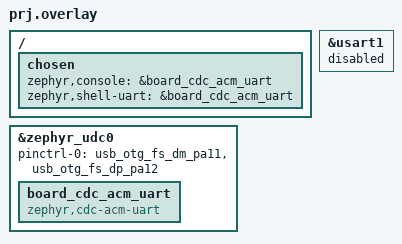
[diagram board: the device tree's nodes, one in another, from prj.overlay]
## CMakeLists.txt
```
cmake_minimum_required(VERSION 3.20.0)

# If a project devicetree overlay exists, pass it to the Zephyr build
# so the overlay is applied during the initial configure step.
if(EXISTS "${CMAKE_CURRENT_SOURCE_DIR}/prj.overlay")
	set(DTC_OVERLAY_FILE "${CMAKE_CURRENT_SOURCE_DIR}/prj.overlay" CACHE STRING "Device tree overlay file for project")
endif()

find_package(Zephyr REQUIRED HINTS $ENV{ZEPHYR_BASE})

project(stm32f411_template)

target_sources(app PRIVATE src/main.c)
```

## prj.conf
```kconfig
# STM32F411 template – Kconfig fragments
# Board: blackpill_f411ce  (WeAct BlackPill STM32F411CEU6)
# Build: cmake -B build -DBOARD=blackpill_f411ce . && cmake --build build -j4

CONFIG_GPIO=y

# Enable USB device stack and CDC-ACM (USB serial)
CONFIG_USB_DEVICE_STACK=y
CONFIG_USB_CDC_ACM=y

# Route console/printk to the console backend (which will be the CDC ACM device)
CONFIG_CONSOLE=y
CONFIG_STDOUT_CONSOLE=y
CONFIG_PRINTK=y
CONFIG_LOG=y
# Lower default log level to reduce driver debug noise on CDC
# 3 = LOG_LEVEL_INF
CONFIG_LOG_DEFAULT_LEVEL=3

# Enable the UART console so the CDC ACM UART driver can be used
CONFIG_UART_CONSOLE=y

# Use the UART log backend (the CDC ACM node exposes a UART device)
CONFIG_LOG_BACKEND_UART=y
CONFIG_LOG_BACKEND_UART_AUTOSTART=y

# USB Device identity - override the Zephyr test defaults
# Replace these with your vendor's assigned IDs for production
CONFIG_USB_DEVICE_VID=0x0483
CONFIG_USB_DEVICE_PID=0x5740
CONFIG_USB_DEVICE_MANUFACTURER="WeAct"
CONFIG_USB_DEVICE_PRODUCT="BlackPill F411 CDC"

# Per-module USB log levels are controlled indirectly; use `CONFIG_LOG_DEFAULT_LEVEL` above.
```

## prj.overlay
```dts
/* Project devicetree overlay: route console to USB CDC ACM */

/ {
    chosen {
        zephyr,console = &board_cdc_acm_uart;
        zephyr,shell-uart = &board_cdc_acm_uart;
    };
};

&zephyr_udc0 {
    /* DP/DM pins for the STM32 USB driver; omit VBUS pin to disable hardware sensing */
    pinctrl-0 = <&usb_otg_fs_dm_pa11 &usb_otg_fs_dp_pa12>;
    pinctrl-names = "default";

    board_cdc_acm_uart: board_cdc_acm_uart {
        compatible = "zephyr,cdc-acm-uart";
        status = "okay";
    };
};

/* Disable onboard USART1 so it doesn't claim PA9 (VBUS) on this board */
&usart1 {
    status = "disabled";
};
```

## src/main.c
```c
/**
 * STM32F411 Template - Zephyr RTOS v4.2.2
 * Board  : blackpill_f411ce (WeAct BlackPill STM32F411CEU6)
 * LED    : PC13 (aliased as led0 in board DTS)
 *
 * Build (container):
 *   cmake -B build -DBOARD=blackpill_f411ce . && cmake --build build -j4
 *
 * Flash (Windows host - host-only):
 *   openocd -f interface/stlink.cfg -f target/stm32f4x.cfg
 *           -c "program build/zephyr/zephyr.elf verify reset exit"
 */

#include <zephyr/kernel.h>
#include <zephyr/drivers/gpio.h>
#include <zephyr/usb/usb_device.h>
#include <zephyr/sys/printk.h>
#include <zephyr/logging/log.h>
#include <zephyr/device.h>
#include <zephyr/devicetree.h>
#include <zephyr/drivers/uart.h>

#define LED0_NODE DT_ALIAS(led0)

LOG_MODULE_REGISTER(app, LOG_LEVEL_INF);

static const struct gpio_dt_spec led = GPIO_DT_SPEC_GET(LED0_NODE, gpios);

static void usb_status_cb(enum usb_dc_status_code status, const uint8_t *param)
{
    switch (status) {
    case USB_DC_CONNECTED:
        LOG_INF("USB status: CONNECTED");
        break;
    case USB_DC_DISCONNECTED:
        LOG_INF("USB status: DISCONNECTED");
        break;
    case USB_DC_CONFIGURED:
        LOG_INF("USB status: CONFIGURED");

        /* Try a direct UART write to the chosen console (CDC ACM) to verify output */
        {
            const struct device *cdc = DEVICE_DT_GET(DT_CHOSEN(zephyr_console));
            const char msg[] = "Hello CDC: USB configured\r\n";

            if (device_is_ready(cdc)) {
                for (size_t i = 0; i < sizeof(msg) - 1; i++) {
                    uart_poll_out(cdc, msg[i]);
                }
            } else {
                LOG_WRN("CDC console device not ready yet");
            }
        }
        break;
    case USB_DC_ERROR:
        LOG_ERR("USB status: ERROR");
        break;
    default:
        LOG_INF("USB status: %d", status);
        break;
    }
}

int main(void)
{
    int ret;
    const struct device *cdc = DEVICE_DT_GET(DT_CHOSEN(zephyr_console));

    gpio_pin_configure_dt(&led, GPIO_OUTPUT_ACTIVE);

    /* Enable USB device stack so console/logging goes over CDC ACM */
    LOG_INF("Enabling USB device stack");
    ret = usb_enable(usb_status_cb);
    if (ret) {
        LOG_ERR("usb_enable failed: %d", ret);
    } else {
        LOG_INF("usb_enable returned 0 (OK)");
    }

    while (1)
    {
        gpio_pin_toggle_dt(&led);
        k_msleep(500);
        LOG_INF("LED toggled");

        /* Send a short message over CDC (chosen console) if ready */
        if (device_is_ready(cdc)) {
            const char msg[] = "CDC loop: alive\r\n";
            for (size_t i = 0; i < sizeof(msg) - 1; i++) {
                uart_poll_out(cdc, msg[i]);
            }
        } else {
            LOG_DBG("CDC console not ready in loop");
        }
    }

    return 0;
}
```
